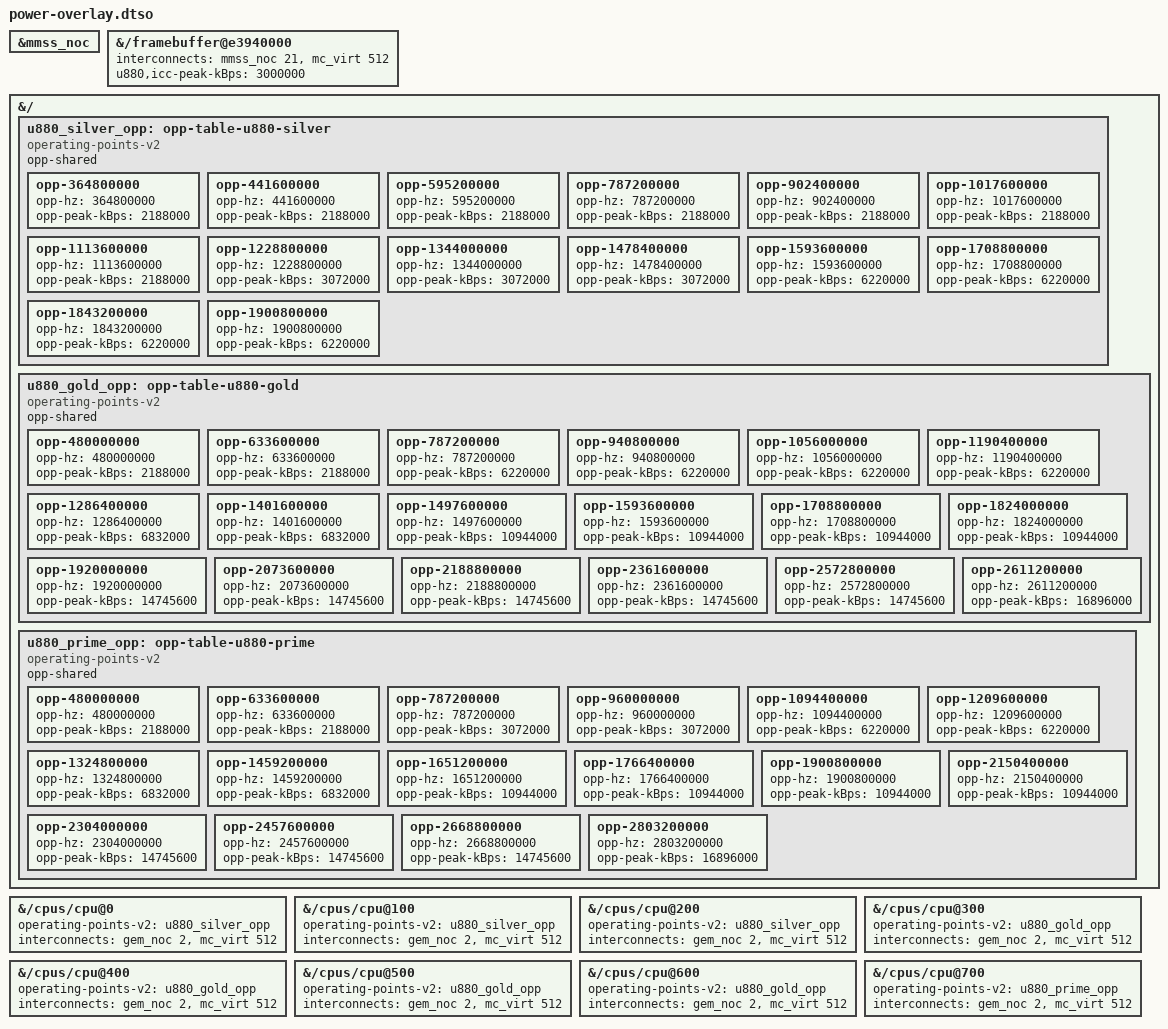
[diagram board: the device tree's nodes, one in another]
// SPDX-License-Identifier: GPL-2.0-only
/* Generated by scripts/gen-power-overlay.py - edit the script. */
/dts-v1/;
/plugin/;

&mmss_noc {
	status = "okay";
};

&{/framebuffer@e3940000} {
	interconnects = <&mmss_noc 21 &mc_virt 512>;  /* MASTER_MDP -> SLAVE_EBI1 */
	interconnect-names = "mdp0-mem";
	u880,icc-peak-kBps = <3000000>;
};

&{/} {
	u880_silver_opp: opp-table-u880-silver {
		compatible = "operating-points-v2";
		opp-shared;
		opp-364800000 {
			opp-hz = /bits/ 64 <364800000>;
			opp-peak-kBps = <2188000>;
		};
		opp-441600000 {
			opp-hz = /bits/ 64 <441600000>;
			opp-peak-kBps = <2188000>;
		};
		opp-595200000 {
			opp-hz = /bits/ 64 <595200000>;
			opp-peak-kBps = <2188000>;
		};
		opp-787200000 {
			opp-hz = /bits/ 64 <787200000>;
			opp-peak-kBps = <2188000>;
		};
		opp-902400000 {
			opp-hz = /bits/ 64 <902400000>;
			opp-peak-kBps = <2188000>;
		};
		opp-1017600000 {
			opp-hz = /bits/ 64 <1017600000>;
			opp-peak-kBps = <2188000>;
		};
		opp-1113600000 {
			opp-hz = /bits/ 64 <1113600000>;
			opp-peak-kBps = <2188000>;
		};
		opp-1228800000 {
			opp-hz = /bits/ 64 <1228800000>;
			opp-peak-kBps = <3072000>;
		};
		opp-1344000000 {
			opp-hz = /bits/ 64 <1344000000>;
			opp-peak-kBps = <3072000>;
		};
		opp-1478400000 {
			opp-hz = /bits/ 64 <1478400000>;
			opp-peak-kBps = <3072000>;
		};
		opp-1593600000 {
			opp-hz = /bits/ 64 <1593600000>;
			opp-peak-kBps = <6220000>;
		};
		opp-1708800000 {
			opp-hz = /bits/ 64 <1708800000>;
			opp-peak-kBps = <6220000>;
		};
		opp-1843200000 {
			opp-hz = /bits/ 64 <1843200000>;
			opp-peak-kBps = <6220000>;
		};
		opp-1900800000 {
			opp-hz = /bits/ 64 <1900800000>;
			opp-peak-kBps = <6220000>;
		};
	};
	u880_gold_opp: opp-table-u880-gold {
		compatible = "operating-points-v2";
		opp-shared;
		opp-480000000 {
			opp-hz = /bits/ 64 <480000000>;
			opp-peak-kBps = <2188000>;
		};
		opp-633600000 {
			opp-hz = /bits/ 64 <633600000>;
			opp-peak-kBps = <2188000>;
		};
		opp-787200000 {
			opp-hz = /bits/ 64 <787200000>;
			opp-peak-kBps = <6220000>;
		};
		opp-940800000 {
			opp-hz = /bits/ 64 <940800000>;
			opp-peak-kBps = <6220000>;
		};
		opp-1056000000 {
			opp-hz = /bits/ 64 <1056000000>;
			opp-peak-kBps = <6220000>;
		};
		opp-1190400000 {
			opp-hz = /bits/ 64 <1190400000>;
			opp-peak-kBps = <6220000>;
		};
		opp-1286400000 {
			opp-hz = /bits/ 64 <1286400000>;
			opp-peak-kBps = <6832000>;
		};
		opp-1401600000 {
			opp-hz = /bits/ 64 <1401600000>;
			opp-peak-kBps = <6832000>;
		};
		opp-1497600000 {
			opp-hz = /bits/ 64 <1497600000>;
			opp-peak-kBps = <10944000>;
		};
		opp-1593600000 {
			opp-hz = /bits/ 64 <1593600000>;
			opp-peak-kBps = <10944000>;
		};
		opp-1708800000 {
			opp-hz = /bits/ 64 <1708800000>;
			opp-peak-kBps = <10944000>;
		};
		opp-1824000000 {
			opp-hz = /bits/ 64 <1824000000>;
			opp-peak-kBps = <10944000>;
		};
		opp-1920000000 {
			opp-hz = /bits/ 64 <1920000000>;
			opp-peak-kBps = <14745600>;
		};
		opp-2073600000 {
			opp-hz = /bits/ 64 <2073600000>;
			opp-peak-kBps = <14745600>;
		};
		opp-2188800000 {
			opp-hz = /bits/ 64 <2188800000>;
			opp-peak-kBps = <14745600>;
		};
		opp-2361600000 {
			opp-hz = /bits/ 64 <2361600000>;
			opp-peak-kBps = <14745600>;
		};
		opp-2572800000 {
			opp-hz = /bits/ 64 <2572800000>;
			opp-peak-kBps = <14745600>;
		};
		opp-2611200000 {
			opp-hz = /bits/ 64 <2611200000>;
			opp-peak-kBps = <16896000>;
		};
	};
	u880_prime_opp: opp-table-u880-prime {
		compatible = "operating-points-v2";
		opp-shared;
		opp-480000000 {
			opp-hz = /bits/ 64 <480000000>;
			opp-peak-kBps = <2188000>;
		};
		opp-633600000 {
			opp-hz = /bits/ 64 <633600000>;
			opp-peak-kBps = <2188000>;
		};
		opp-787200000 {
			opp-hz = /bits/ 64 <787200000>;
			opp-peak-kBps = <3072000>;
		};
		opp-960000000 {
			opp-hz = /bits/ 64 <960000000>;
			opp-peak-kBps = <3072000>;
		};
		opp-1094400000 {
			opp-hz = /bits/ 64 <1094400000>;
			opp-peak-kBps = <6220000>;
		};
		opp-1209600000 {
			opp-hz = /bits/ 64 <1209600000>;
			opp-peak-kBps = <6220000>;
		};
		opp-1324800000 {
			opp-hz = /bits/ 64 <1324800000>;
			opp-peak-kBps = <6832000>;
		};
		opp-1459200000 {
			opp-hz = /bits/ 64 <1459200000>;
			opp-peak-kBps = <6832000>;
		};
		opp-1651200000 {
			opp-hz = /bits/ 64 <1651200000>;
			opp-peak-kBps = <10944000>;
		};
		opp-1766400000 {
			opp-hz = /bits/ 64 <1766400000>;
			opp-peak-kBps = <10944000>;
		};
		opp-1900800000 {
			opp-hz = /bits/ 64 <1900800000>;
			opp-peak-kBps = <10944000>;
		};
		opp-2150400000 {
			opp-hz = /bits/ 64 <2150400000>;
			opp-peak-kBps = <10944000>;
		};
		opp-2304000000 {
			opp-hz = /bits/ 64 <2304000000>;
			opp-peak-kBps = <14745600>;
		};
		opp-2457600000 {
			opp-hz = /bits/ 64 <2457600000>;
			opp-peak-kBps = <14745600>;
		};
		opp-2668800000 {
			opp-hz = /bits/ 64 <2668800000>;
			opp-peak-kBps = <14745600>;
		};
		opp-2803200000 {
			opp-hz = /bits/ 64 <2803200000>;
			opp-peak-kBps = <16896000>;
		};
	};
};

&{/cpus/cpu@0} {
	operating-points-v2 = <&u880_silver_opp>;
	interconnects = <&gem_noc 2 &mc_virt 512>;  /* MASTER_APPSS_PROC -> SLAVE_EBI1 */
};

&{/cpus/cpu@100} {
	operating-points-v2 = <&u880_silver_opp>;
	interconnects = <&gem_noc 2 &mc_virt 512>;  /* MASTER_APPSS_PROC -> SLAVE_EBI1 */
};

&{/cpus/cpu@200} {
	operating-points-v2 = <&u880_silver_opp>;
	interconnects = <&gem_noc 2 &mc_virt 512>;  /* MASTER_APPSS_PROC -> SLAVE_EBI1 */
};

&{/cpus/cpu@300} {
	operating-points-v2 = <&u880_gold_opp>;
	interconnects = <&gem_noc 2 &mc_virt 512>;  /* MASTER_APPSS_PROC -> SLAVE_EBI1 */
};

&{/cpus/cpu@400} {
	operating-points-v2 = <&u880_gold_opp>;
	interconnects = <&gem_noc 2 &mc_virt 512>;  /* MASTER_APPSS_PROC -> SLAVE_EBI1 */
};

&{/cpus/cpu@500} {
	operating-points-v2 = <&u880_gold_opp>;
	interconnects = <&gem_noc 2 &mc_virt 512>;  /* MASTER_APPSS_PROC -> SLAVE_EBI1 */
};

&{/cpus/cpu@600} {
	operating-points-v2 = <&u880_gold_opp>;
	interconnects = <&gem_noc 2 &mc_virt 512>;  /* MASTER_APPSS_PROC -> SLAVE_EBI1 */
};

&{/cpus/cpu@700} {
	operating-points-v2 = <&u880_prime_opp>;
	interconnects = <&gem_noc 2 &mc_virt 512>;  /* MASTER_APPSS_PROC -> SLAVE_EBI1 */
};
